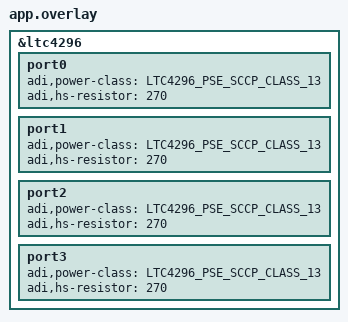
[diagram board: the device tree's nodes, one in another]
&ltc4296 {
        port0 {
                adi,power-class = <LTC4296_PSE_SCCP_CLASS_13>;
                adi,hs-resistor = <270>;
        };

        port1 {
                adi,power-class = <LTC4296_PSE_SCCP_CLASS_13>;
                adi,hs-resistor = <270>;
        };

        port2 {
                adi,power-class = <LTC4296_PSE_SCCP_CLASS_13>;
                adi,hs-resistor = <270>;
        };

        port3 {
                adi,power-class = <LTC4296_PSE_SCCP_CLASS_13>;
                adi,hs-resistor = <270>;
        };
};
